# PIC32CZ8110CA90144 register map
Vendor: Microchip Technology; Series: PIC32CZCA90; File version: 0
CPU: CM7 r1p1, little endian, MPU, FPU, double-precision FPU, I-cache, D-cache, ITCM, DTCM, 3 interrupt priority bits, 222 interrupts
Registers are 32-bit, read-write, reset 0x0 unless marked. A register's access mark holds for its fields unless they carry their own. Offsets are from the block's base; [hi:lo] are bit positions; {n}, {i} and the like mark numbered series.

## MLB — Media Local Bus
Base 0x458C0000
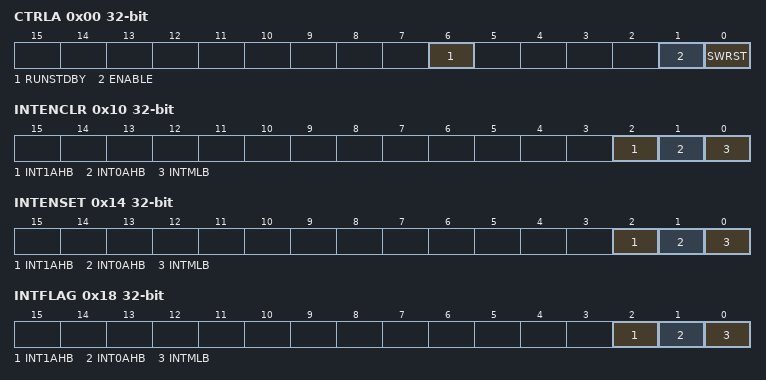
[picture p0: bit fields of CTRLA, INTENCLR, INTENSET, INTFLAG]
0x00 CTRLA — MLB Wrapper Control Register
  [6] RUNSTDBY — Run In Standby
  [1] ENABLE — MediaLB Enable (ON) bit
  [0] SWRST — Software Reset
0x10 INTENCLR write-1-clears — Interrupt Enable Clear Register
  [2] INT1AHB — AHB Interrupt 1 Enable Clear
  [1] INT0AHB — AHB Interrupt 0 Enable Clear
  [0] INTMLB — MLB General Interrupt Enable Clear
0x14 INTENSET write-1-sets — Interrupt Enable Set Register
  [2] INT1AHB — AHB Interrupt 1 Enable Set
  [1] INT0AHB — AHB Interrupt 0 Enable Set
  [0] INTMLB — MLB General Interrupt Enable Set
0x18 INTFLAG write-1-clears — Interrupt Status and Clear Register
  [2] INT1AHB — AHB Interrupt 1 Flag
  [1] INT0AHB — AHB Interrupt 0 Flag
  [0] INTMLB — MLB General Interrupt Flag
0x1C DBGCTRL — Debug Control Register
  [0] DBGRUN — Debug Run Enable
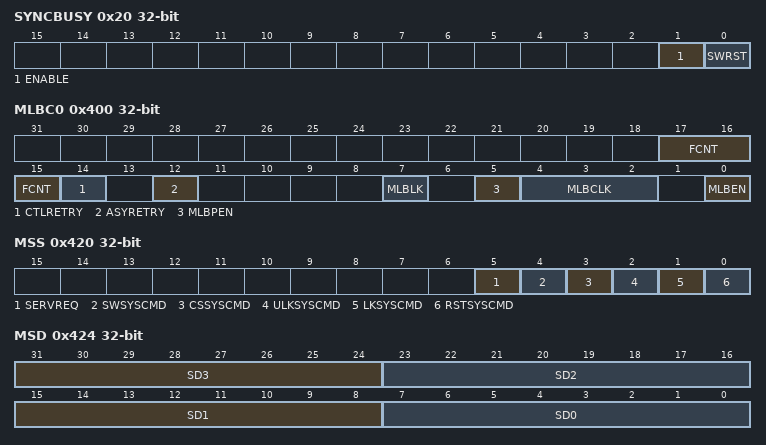
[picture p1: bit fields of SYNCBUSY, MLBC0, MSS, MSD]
0x20 SYNCBUSY ro
  [1] ENABLE — Module Enable Synchronization Busy
  [0] SWRST — Software Reset Synchronization Busy
0x400 MLBC0 — MediaLB Control 0 Register
  [17:15] FCNT — Number of frames per sub-buffer (synchronous channels)
  [14] CTLRETRY — Control Tx packet retry
  [12] ASYRETRY — Asynchronous Tx packet retry
  [7] MLBLK — MediaLB lock status (read-only)
  [5] MLBPEN — MediaLB 6-pin enable.
  [4:2] MLBCLK — MediaLB clock speed select
    0=256xFs (256x Frame Speed); 1=512xFs (512x Frame Speed); 2=1024xFs (1024x Frame Speed)
  [0] MLBEN — MediaLB enable
0x40C MS0 — MediaLB Channel Status 0 Register
  [31:0] MCS — MediaLB channel status (for channels 31 to 0)
0x414 MS1 — MediaLB Channel Status 1 Register
  [31:0] MCS — MediaLB channel status (for channels 63 to 32)
0x420 MSS — MediaLB System Status Register
  [5] SERVREQ — Service request enable
  [4] SWSYSCMD — Software system command detected
  [3] CSSYSCMD — Channel scan system command detected
  [2] ULKSYSCMD — Network unlock system command detected
  [1] LKSYSCMD — Network lock system command detected
  [0] RSTSYSCMD — Reset system command detected
0x424 MSD ro — MediaLB System Data Register (Read-only)
  [31:24] SD3 — System data (byte 3) - MSB
  [23:16] SD2 — System data (byte 2)
  [15:8] SD1 — System data (byte 1)
  [7:0] SD0 — System data (byte 0) - LSB
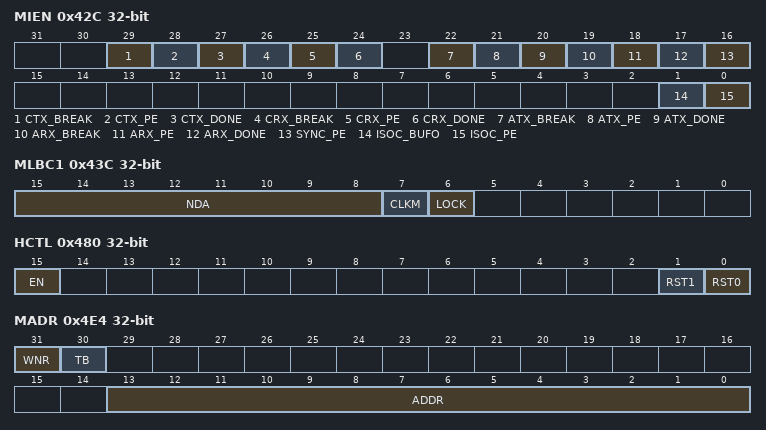
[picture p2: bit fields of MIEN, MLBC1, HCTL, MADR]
0x42C MIEN — MediaLB Interrupt Enable Register
  [29] CTX_BREAK — Control Tx break enable
  [28] CTX_PE — Control Tx protocol error enable
  [27] CTX_DONE — Control Tx packet done enable
  [26] CRX_BREAK — Control Rx break enable
  [25] CRX_PE — Control Rx protocol error enable
  [24] CRX_DONE — Control Rx packet done enable
  [22] ATX_BREAK — Asynchronous Tx break enable
  [21] ATX_PE — Asynchronous Tx protocol error enable
  [20] ATX_DONE — Asynchronous Tx packet done enable
  [19] ARX_BREAK — Asynchronous Rx break enable
  [18] ARX_PE — Asynchronous Rx protocol error enable
  [17] ARX_DONE — Asynchronous Rx packet done enable
  [16] SYNC_PE — Synchronous protocol error enable
  [1] ISOC_BUFO — Isochronous Rx buffer overflow enable
  [0] ISOC_PE — Isochronous Rx protocol error enable
0x43C MLBC1 — MediaLB Control 1 Register
  [15:8] NDA — Node device address
  [7] CLKM — MediaLB clock missing status
  [6] LOCK — MediaLB lock error status
0x480 HCTL — HBI Control Register
  [15] EN — HBI enable: 1 = enabled, 0 = disabled
  [1] RST1 — AGU1 software reset: 1 = reset active, 0 = reset inactive
  [0] RST0 — AGU0 software reset: 1 = reset active, 0 = reset inactive
0x488 HCMR0 — HBI Channel Mask 0 Register
  [31:0] CHM — Bitwise channel mask bit: 0 = masked, 1 = unmasked
0x48C HCMR1 — HBI Channel Mask 1 Register
  [31:0] CHM — Bitwise channel mask bit: 0 = masked, 1 = unmasked
0x490 HCER0 — HBI Channel Error 0 Register
  [31:0] CERR — Bitwise channel error bit
0x494 HCER1 — HBI Channel Error 1 Register
  [31:0] CERR — Bitwise channel error bit
0x498 HCBR0 ro — HBI Channel Busy 0 Register
  [31:0] CHB — Bitwise channel busy bit: 0 = idle, 1 = busy
0x49C HCBR1 ro — HBI Channel Busy 1 Register
  [31:0] CHB — Bitwise channel busy bit: 0 = idle, 1 = busy
0x4C0 MDAT0 — MIF Data 0 Register
  [31:0] DATA — CTR data - bits[31:0] of 128-bit entry or DBR data - bits[7:0] of 8-bit entry
{0x4C0+4i} MDAT{i} (i=1..3) — MIF Data {i} Register
  [31:0] DATA — CTR data - bits[{32i+31}:{32i}] of 128-bit entry
{0x4D0+4i} MDWE{i} (i=0..3) — MIF Data Write Enable {i} Register
  [31:0] MASK — Bitwise write enable for CTR data - bits[{32i+31}:{32i}] (0 = disabled, 1 = enabled)
0x4E0 MCTL — MIF Control Register
  [0] XCMP — Transfer complete (write 0 to clear)
0x4E4 MADR — MIF Address Register
  [31] WNR — Write-Not-Read selection (0 = read, 1 = write)
  [30] TB — Target location bit (0 = selects CTR, 1 = selects DBR)
  [13:0] ADDR — DBR address of 8-bit entry - bits[13:8].CTR address of 128-bit entry or DBR address of 8-bit entry - bits[7:0]
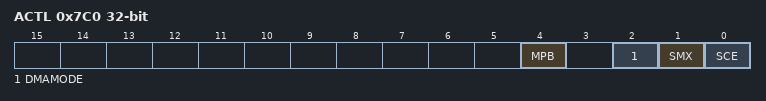
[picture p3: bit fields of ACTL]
0x7C0 ACTL — AHB Control Register
  [4] MPB — Packet buffering mode: 0 = single-packet mode 1 = multiple-packet mode
  [2] DMAMODE — DMA Mode: 0 = DMA Mode 0 1 = DMA Mode 1
  [1] SMX — AHB interrupt mux enable: 0 = ACSR0 generates an interrupt on ahb_int[0]; ACSR1 generates an interrupt on ahb_int[1] 1 = ACSR0 and ACSR1 generate an interrupts on ahb_int[0] only
  [0] SCE — Software clear enable: 0 = Hardware clears interrupt after a ACSRn register read 1 = Software clears interrupt
0x7D0 ACSR0 write-1-clears — AHB Channel Status 0 Register
  [31:0] CHS — Interrupt status for logical channels 31 to 0: 0 = None 1 = Interrupt
0x7D4 ACSR1 write-1-clears — AHB Channel Status 1 Register
  [31:0] CHS — Interrupt status for logical channels 63 to 32: 0 = None 1 = Interrupt
0x7D8 ACMR0 — AHB Channel Mask 0 Register
  [31:0] CHM — Bitwise channel mask bit:0 = Masked 1 = Unmasked
0x7DC ACMR1 — AHB Channel Mask 1 Register
  [31:0] CHM — Bitwise channel mask bit:0 = Masked 1 = Unmasked

## Notices in the file
Copyright (c) 2026 Microchip Technology Inc.
SPDX-License-Identifier: Apache-2.0
Licensed under the Apache License, Version 2.0 (the "License");
you may not use this file except in compliance with the License.
You may obtain a copy of the License at
http://www.apache.org/licenses/LICENSE-2.0
Unless required by applicable law or agreed to in writing, software
distributed under the License is distributed on an "AS IS" BASIS,
WITHOUT WARRANTIES OR CONDITIONS OF ANY KIND, either express or implied.
See the License for the specific language governing permissions and
limitations under the License.
